# STM32WBA35_USB_PMA register map
File version: 1.6
STM32WBA35 PMA
Registers are 16-bit, read-write, reset 0x0 unless marked. A register's access mark holds for its fields unless they carry their own. Offsets are from the block's base; lines under a group give offsets from that group; [hi:lo] are bit positions; {n}, {i} and the like mark numbered series; 'fields as' and 'values as' point back to an identical list; <NAME> marks a mode.

## Memory map
0x40006C00 USB_PMA size 0x400 — USB_PMA2

## USB_PMA — USB_PMA2
Base 0x40006C00
{0x0+8i} ADDR{i}_TX (i=0..3) — See p.2013
{0x2+8i} COUNT{i}_TX (i=0..3) — USB endpoint n register
  [9:0] COUNT{i}_TX
{0x4+8i} ADDR{i}_RX (i=0..3) — USB endpoint n register
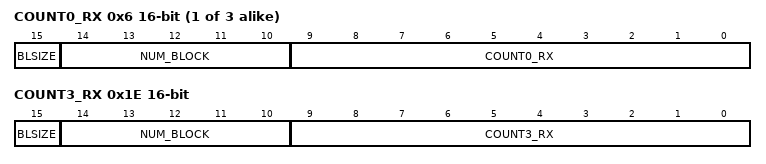
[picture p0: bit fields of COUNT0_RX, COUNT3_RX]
{0x6+8i} COUNT{i}_RX (i=0..2) — USB endpoint n register
  [15] BLSIZE — 0: 2 byte block size; 1: 32 byte block size
  [14:10] NUM_BLOCK — For 32 byte blocks, 0 = 32 bytes, 1 = 64 bytes; 2 = 96 bytes etc
  [9:0] COUNT{i}_RX
0x1E COUNT3_RX — USB endpoint n register
  [15] BLSIZE — 0: 2 byte block size; 1: 32 byte block size
  [14:10] NUM_BLOCK — For 32 byte blocks, 0 = 32 bytes, 1 = 64 bytes; 2 = 96 bytes etc
  [9:0] COUNT3_RX — COUNT2_RX
0x20 EP0_RX_BUFFER — USB endpoint n register
  [15:0] BUFF0
0x22 EP0_RX_BUFFER2 — USB endpoint n register
  [15:0] BUFF0
0x58 EP0_TX_BUFFER 32-bit — USB endpoint n register
  [31:0] BUFF0
